# BL808 register map
File version: 0.1
Registers are access not given, no defined reset value unless marked. A register's access mark holds for its fields unless they carry their own. Offsets are from the block's base; [hi:lo] are bit positions; {n}, {i} and the like mark numbered series.

## MJPEG_Q
Base 0x30021000
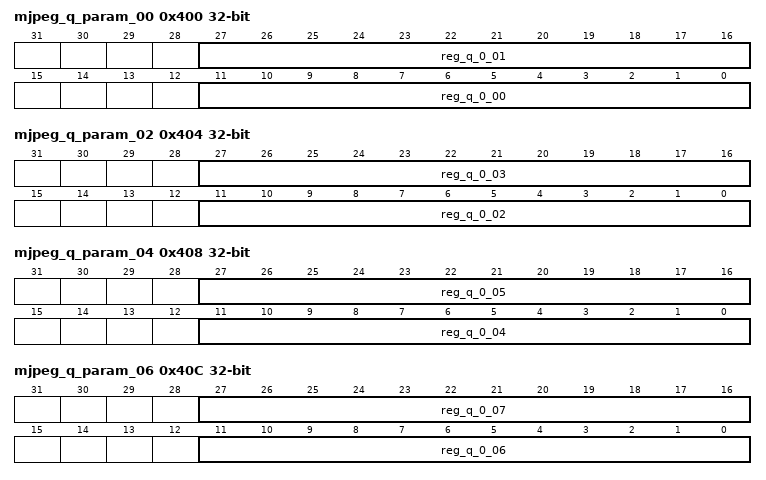
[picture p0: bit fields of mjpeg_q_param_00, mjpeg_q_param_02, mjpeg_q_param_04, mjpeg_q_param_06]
0x400 mjpeg_q_param_00
  [27:16] reg_q_0_01 rw, [11:0] reg_q_0_00 rw
0x404 mjpeg_q_param_02
  [27:16] reg_q_0_03 rw, [11:0] reg_q_0_02 rw
0x408 mjpeg_q_param_04
  [27:16] reg_q_0_05 rw, [11:0] reg_q_0_04 rw
0x40C mjpeg_q_param_06
  [27:16] reg_q_0_07 rw, [11:0] reg_q_0_06 rw
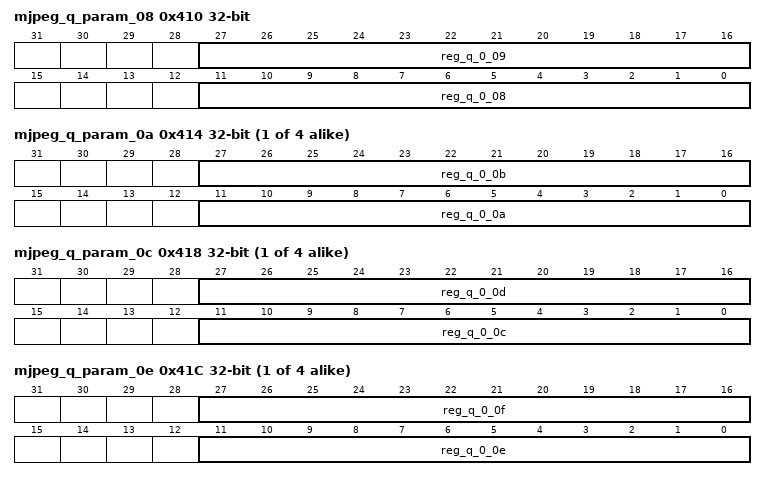
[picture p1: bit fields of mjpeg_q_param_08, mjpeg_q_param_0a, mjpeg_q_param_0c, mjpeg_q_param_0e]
0x410 mjpeg_q_param_08
  [27:16] reg_q_0_09 rw, [11:0] reg_q_0_08 rw
{0x414+0x20*i} mjpeg_q_param_{i}a (i=0..3)
  [27:16] reg_q_0_{i}b rw, [11:0] reg_q_0_{i}a rw
{0x418+0x20*i} mjpeg_q_param_{i}c (i=0..3)
  [27:16] reg_q_0_{i}d rw, [11:0] reg_q_0_{i}c rw
{0x41C+0x20*i} mjpeg_q_param_{i}e (i=0..3)
  [27:16] reg_q_0_{i}f rw, [11:0] reg_q_0_{i}e rw
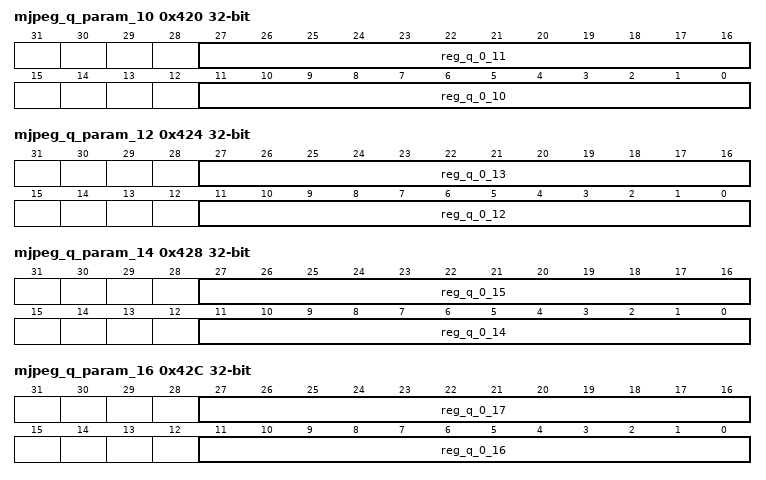
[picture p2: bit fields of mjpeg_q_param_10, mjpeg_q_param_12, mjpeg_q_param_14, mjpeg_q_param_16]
0x420 mjpeg_q_param_10
  [27:16] reg_q_0_11 rw, [11:0] reg_q_0_10 rw
0x424 mjpeg_q_param_12
  [27:16] reg_q_0_13 rw, [11:0] reg_q_0_12 rw
0x428 mjpeg_q_param_14
  [27:16] reg_q_0_15 rw, [11:0] reg_q_0_14 rw
0x42C mjpeg_q_param_16
  [27:16] reg_q_0_17 rw, [11:0] reg_q_0_16 rw
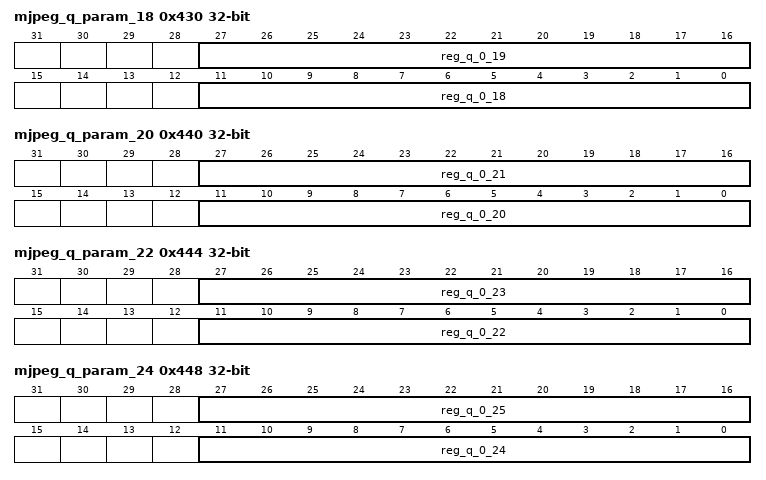
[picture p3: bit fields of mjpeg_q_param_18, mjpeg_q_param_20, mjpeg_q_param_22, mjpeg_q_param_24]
0x430 mjpeg_q_param_18
  [27:16] reg_q_0_19 rw, [11:0] reg_q_0_18 rw
0x440 mjpeg_q_param_20
  [27:16] reg_q_0_21 rw, [11:0] reg_q_0_20 rw
0x444 mjpeg_q_param_22
  [27:16] reg_q_0_23 rw, [11:0] reg_q_0_22 rw
0x448 mjpeg_q_param_24
  [27:16] reg_q_0_25 rw, [11:0] reg_q_0_24 rw
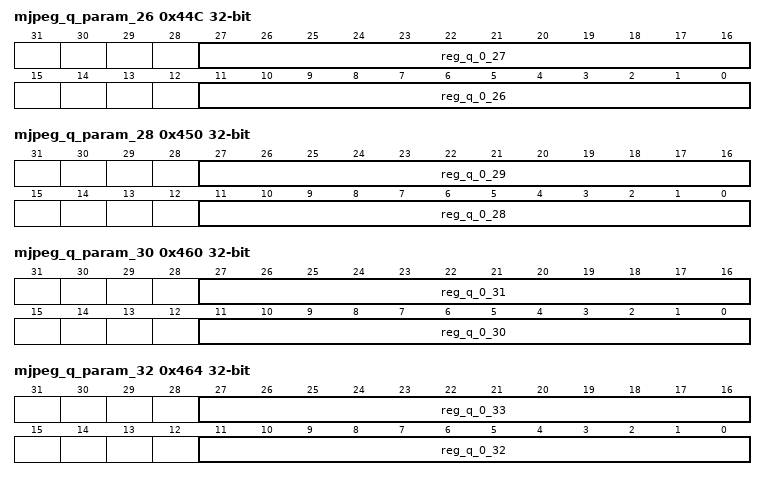
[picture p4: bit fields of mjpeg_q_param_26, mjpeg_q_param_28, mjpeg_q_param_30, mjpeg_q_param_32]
0x44C mjpeg_q_param_26
  [27:16] reg_q_0_27 rw, [11:0] reg_q_0_26 rw
0x450 mjpeg_q_param_28
  [27:16] reg_q_0_29 rw, [11:0] reg_q_0_28 rw
0x460 mjpeg_q_param_30
  [27:16] reg_q_0_31 rw, [11:0] reg_q_0_30 rw
0x464 mjpeg_q_param_32
  [27:16] reg_q_0_33 rw, [11:0] reg_q_0_32 rw
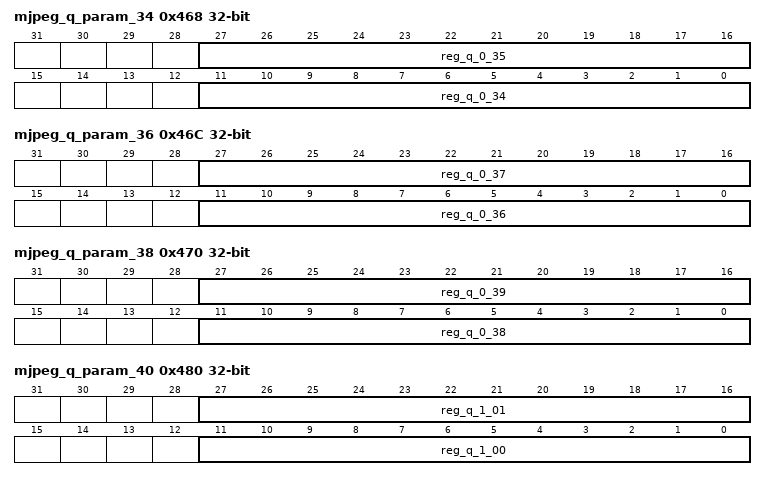
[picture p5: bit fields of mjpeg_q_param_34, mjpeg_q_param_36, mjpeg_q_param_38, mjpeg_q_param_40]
0x468 mjpeg_q_param_34
  [27:16] reg_q_0_35 rw, [11:0] reg_q_0_34 rw
0x46C mjpeg_q_param_36
  [27:16] reg_q_0_37 rw, [11:0] reg_q_0_36 rw
0x470 mjpeg_q_param_38
  [27:16] reg_q_0_39 rw, [11:0] reg_q_0_38 rw
0x480 mjpeg_q_param_40
  [27:16] reg_q_1_01 rw, [11:0] reg_q_1_00 rw
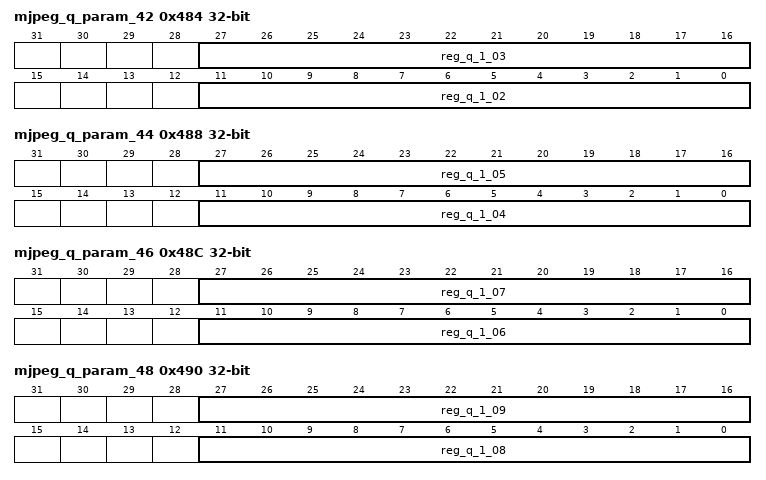
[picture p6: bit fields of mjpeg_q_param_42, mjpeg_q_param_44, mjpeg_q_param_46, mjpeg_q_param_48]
0x484 mjpeg_q_param_42
  [27:16] reg_q_1_03 rw, [11:0] reg_q_1_02 rw
0x488 mjpeg_q_param_44
  [27:16] reg_q_1_05 rw, [11:0] reg_q_1_04 rw
0x48C mjpeg_q_param_46
  [27:16] reg_q_1_07 rw, [11:0] reg_q_1_06 rw
0x490 mjpeg_q_param_48
  [27:16] reg_q_1_09 rw, [11:0] reg_q_1_08 rw
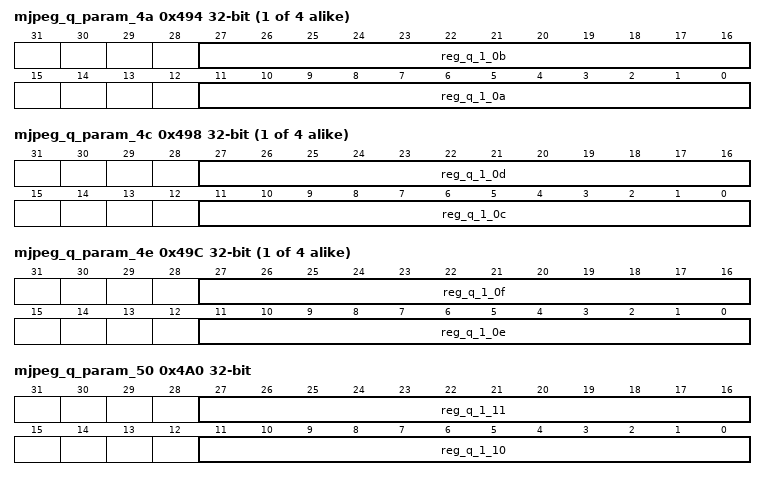
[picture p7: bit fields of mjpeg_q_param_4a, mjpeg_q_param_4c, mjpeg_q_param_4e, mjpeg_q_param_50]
{0x414+0x20*i} mjpeg_q_param_{i}a (i=4..7)
  [27:16] reg_q_1_{i-4}b rw, [11:0] reg_q_1_{i-4}a rw
{0x418+0x20*i} mjpeg_q_param_{i}c (i=4..7)
  [27:16] reg_q_1_{i-4}d rw, [11:0] reg_q_1_{i-4}c rw
{0x41C+0x20*i} mjpeg_q_param_{i}e (i=4..7)
  [27:16] reg_q_1_{i-4}f rw, [11:0] reg_q_1_{i-4}e rw
0x4A0 mjpeg_q_param_50
  [27:16] reg_q_1_11 rw, [11:0] reg_q_1_10 rw
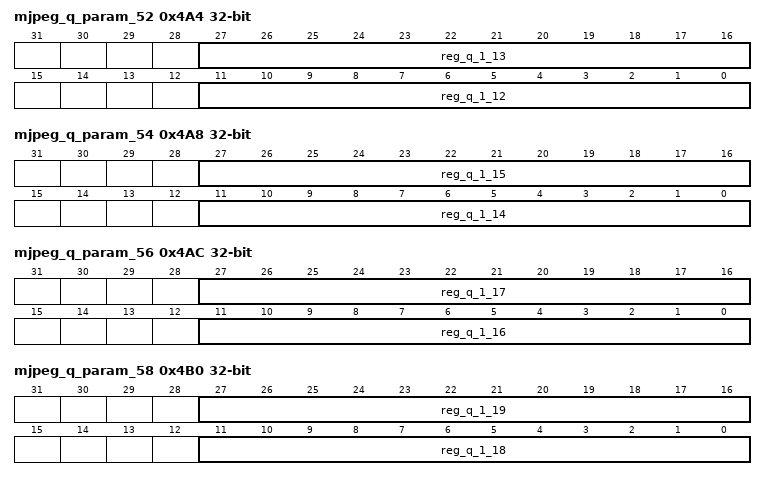
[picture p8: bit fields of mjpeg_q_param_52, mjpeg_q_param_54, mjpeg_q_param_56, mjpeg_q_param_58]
0x4A4 mjpeg_q_param_52
  [27:16] reg_q_1_13 rw, [11:0] reg_q_1_12 rw
0x4A8 mjpeg_q_param_54
  [27:16] reg_q_1_15 rw, [11:0] reg_q_1_14 rw
0x4AC mjpeg_q_param_56
  [27:16] reg_q_1_17 rw, [11:0] reg_q_1_16 rw
0x4B0 mjpeg_q_param_58
  [27:16] reg_q_1_19 rw, [11:0] reg_q_1_18 rw
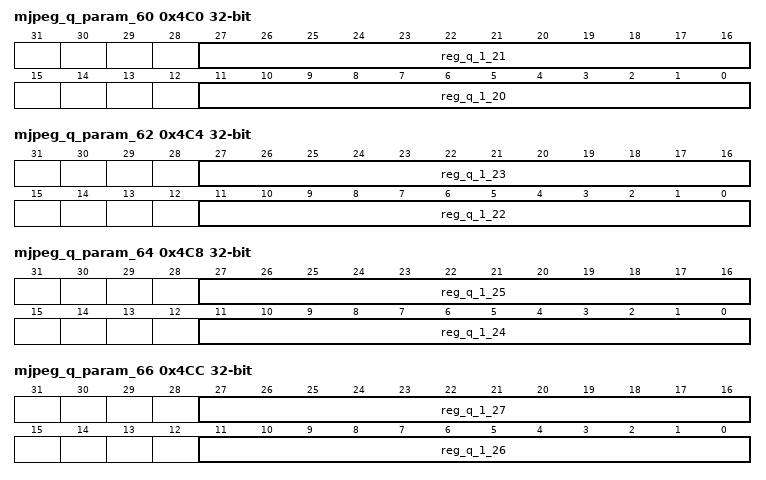
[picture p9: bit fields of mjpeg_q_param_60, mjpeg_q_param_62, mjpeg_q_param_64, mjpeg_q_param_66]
0x4C0 mjpeg_q_param_60
  [27:16] reg_q_1_21 rw, [11:0] reg_q_1_20 rw
0x4C4 mjpeg_q_param_62
  [27:16] reg_q_1_23 rw, [11:0] reg_q_1_22 rw
0x4C8 mjpeg_q_param_64
  [27:16] reg_q_1_25 rw, [11:0] reg_q_1_24 rw
0x4CC mjpeg_q_param_66
  [27:16] reg_q_1_27 rw, [11:0] reg_q_1_26 rw
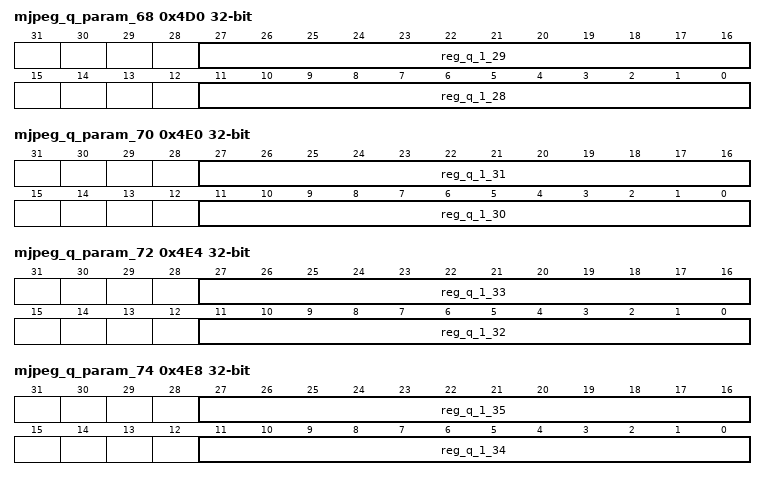
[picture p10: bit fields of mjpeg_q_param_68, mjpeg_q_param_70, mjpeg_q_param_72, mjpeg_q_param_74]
0x4D0 mjpeg_q_param_68
  [27:16] reg_q_1_29 rw, [11:0] reg_q_1_28 rw
0x4E0 mjpeg_q_param_70
  [27:16] reg_q_1_31 rw, [11:0] reg_q_1_30 rw
0x4E4 mjpeg_q_param_72
  [27:16] reg_q_1_33 rw, [11:0] reg_q_1_32 rw
0x4E8 mjpeg_q_param_74
  [27:16] reg_q_1_35 rw, [11:0] reg_q_1_34 rw
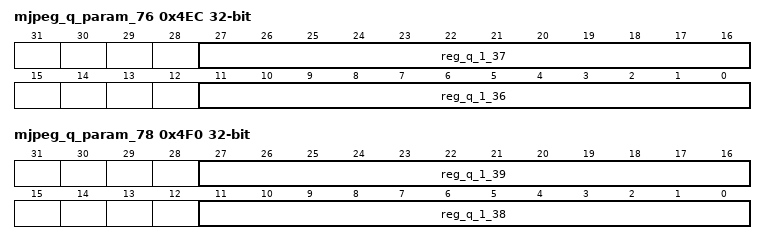
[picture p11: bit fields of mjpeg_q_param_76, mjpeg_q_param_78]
0x4EC mjpeg_q_param_76
  [27:16] reg_q_1_37 rw, [11:0] reg_q_1_36 rw
0x4F0 mjpeg_q_param_78
  [27:16] reg_q_1_39 rw, [11:0] reg_q_1_38 rw

## MJPEG
Base 0x30021000
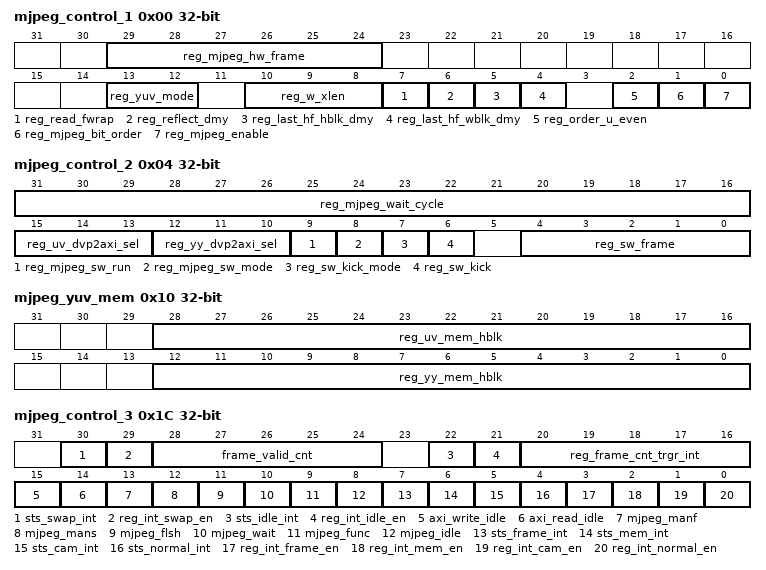
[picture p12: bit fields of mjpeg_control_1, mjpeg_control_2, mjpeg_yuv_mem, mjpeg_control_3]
0x00 mjpeg_control_1
  [29:24] reg_mjpeg_hw_frame rw, [13:12] reg_yuv_mode rw, [10:8] reg_w_xlen rw, [7] reg_read_fwrap rw, [6] reg_reflect_dmy rw, [5] reg_last_hf_hblk_dmy rw, [4] reg_last_hf_wblk_dmy rw, [2] reg_order_u_even rw, [1] reg_mjpeg_bit_order rw, [0] reg_mjpeg_enable rw
0x04 mjpeg_control_2
  [31:16] reg_mjpeg_wait_cycle rw, [15:13] reg_uv_dvp2axi_sel rw, [12:10] reg_yy_dvp2axi_sel rw, [9] reg_mjpeg_sw_run rw, [8] reg_mjpeg_sw_mode rw, [7] reg_sw_kick_mode rw, [6] reg_sw_kick write-once, [4:0] reg_sw_frame rw
0x08 mjpeg_yy_frame_addr rw
  [31:0] reg_yy_addr_start
0x0C mjpeg_uv_frame_addr rw
  [31:0] reg_uv_addr_start
0x10 mjpeg_yuv_mem
  [28:16] reg_uv_mem_hblk rw, [12:0] reg_yy_mem_hblk rw
0x14 jpeg_frame_addr rw
  [31:0] reg_w_addr_start
0x18 jpeg_store_memory rw
  [31:0] reg_w_burst_cnt
0x1C mjpeg_control_3
  [30] sts_swap_int ro, [29] reg_int_swap_en rw, [28:24] frame_valid_cnt ro, [22] sts_idle_int ro, [21] reg_int_idle_en rw, [20:16] reg_frame_cnt_trgr_int rw, [15] axi_write_idle ro, [14] axi_read_idle ro, [13] mjpeg_manf ro, [12] mjpeg_mans ro, [11] mjpeg_flsh ro, [10] mjpeg_wait ro, [9] mjpeg_func ro, [8] mjpeg_idle ro, [7] sts_frame_int ro, [6] sts_mem_int ro, [5] sts_cam_int ro, [4] sts_normal_int ro, [3] reg_int_frame_en rw, [2] reg_int_mem_en rw, [1] reg_int_cam_en rw, [0] reg_int_normal_en rw
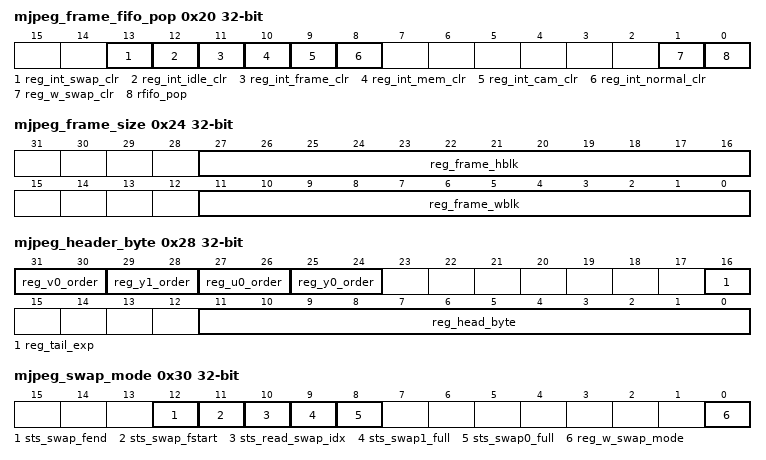
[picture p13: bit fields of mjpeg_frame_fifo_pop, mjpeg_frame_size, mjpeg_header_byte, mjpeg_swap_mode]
0x20 mjpeg_frame_fifo_pop
  [13] reg_int_swap_clr write-once, [12] reg_int_idle_clr write-once, [11] reg_int_frame_clr write-once, [10] reg_int_mem_clr write-once, [9] reg_int_cam_clr write-once, [8] reg_int_normal_clr write-once, [1] reg_w_swap_clr write-once, [0] rfifo_pop write-once
0x24 mjpeg_frame_size
  [27:16] reg_frame_hblk rw, [11:0] reg_frame_wblk rw
0x28 mjpeg_header_byte
  [31:30] reg_v0_order rw, [29:28] reg_y1_order rw, [27:26] reg_u0_order rw, [25:24] reg_y0_order rw, [16] reg_tail_exp rw, [11:0] reg_head_byte rw
0x30 mjpeg_swap_mode
  [12] sts_swap_fend ro, [11] sts_swap_fstart ro, [10] sts_read_swap_idx ro, [9] sts_swap1_full ro, [8] sts_swap0_full ro, [0] reg_w_swap_mode rw
0x34 mjpeg_swap_bit_cnt ro
  [31:0] frame_swap_end_bit_cnt
0x38 mjpeg_yuv_mem_sw
  [12:0] reg_sw_kick_hblk rw
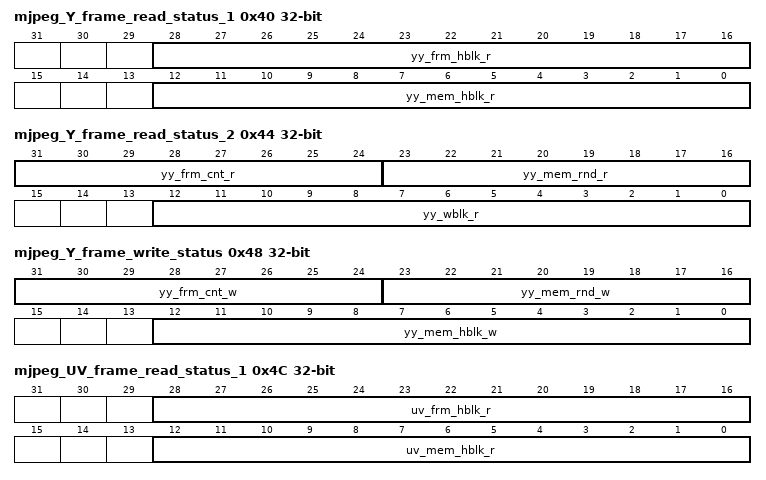
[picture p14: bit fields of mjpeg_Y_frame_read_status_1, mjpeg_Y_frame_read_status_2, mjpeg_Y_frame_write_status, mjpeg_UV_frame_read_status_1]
0x40 mjpeg_Y_frame_read_status_1
  [28:16] yy_frm_hblk_r ro, [12:0] yy_mem_hblk_r ro
0x44 mjpeg_Y_frame_read_status_2
  [31:24] yy_frm_cnt_r ro, [23:16] yy_mem_rnd_r ro, [12:0] yy_wblk_r ro
0x48 mjpeg_Y_frame_write_status
  [31:24] yy_frm_cnt_w ro, [23:16] yy_mem_rnd_w ro, [12:0] yy_mem_hblk_w ro
0x4C mjpeg_UV_frame_read_status_1
  [28:16] uv_frm_hblk_r ro, [12:0] uv_mem_hblk_r ro
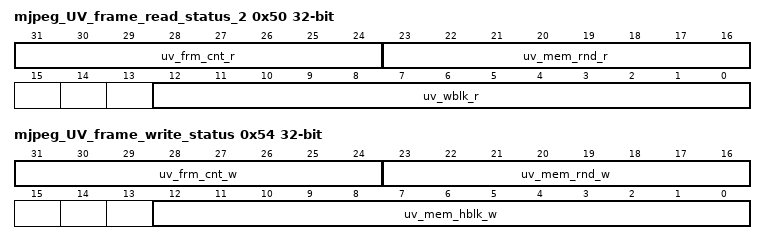
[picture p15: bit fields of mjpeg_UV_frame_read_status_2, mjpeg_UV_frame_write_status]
0x50 mjpeg_UV_frame_read_status_2
  [31:24] uv_frm_cnt_r ro, [23:16] uv_mem_rnd_r ro, [12:0] uv_wblk_r ro
0x54 mjpeg_UV_frame_write_status
  [31:24] uv_frm_cnt_w ro, [23:16] uv_mem_rnd_w ro, [12:0] uv_mem_hblk_w ro
0x58 mjpeg_frame_w_hblk_status
  [28:16] uv_frm_hblk_w ro, [12:0] yy_frm_hblk_w ro
{0x80+8i} mjpeg_start_addr{i} ro (i=0..3)
  [31:0] frame_start_addr_{i}
{0x84+8i} mjpeg_bit_cnt{i} ro (i=0..3)
  [31:0] frame_bit_cnt_{i}
0x100 mjpeg_q_enc
  [25] sts_q_sram_enc ro, [24] reg_q_sram_sw write-once, [n] frame_q_sram_{n} ro (n=0..3)
0x110 mjpeg_frame_id_10 ro
  [31:16] frame_id_1, [15:0] frame_id_0
0x114 mjpeg_frame_id_32 ro
  [31:16] frame_id_3, [15:0] frame_id_2
0x1F0 mjpeg_debug
  [11:8] reg_id_latch_hblk rw, [7:4] reg_mjpeg_dbg_sel rw, [0] reg_mjpeg_dbg_en rw
0x1FC mjpeg_dummy_reg rw
  [31:0] mjpeg_dummy_reg
